VERSION ""

NS_ :

BS_:

BU_: FUSION TBOX

BO_ 1296 NMm_XXX: 8 TBOX

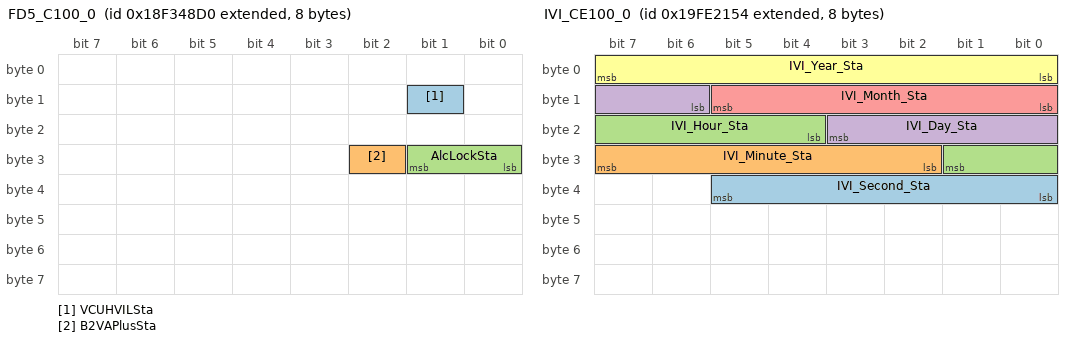
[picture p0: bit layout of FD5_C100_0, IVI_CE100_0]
BO_ 2566080720 FD5_C100_0: 8 FUSION
 SG_ VCUHVILSta : 9|1@1+ (1,0) [0|1] "" Vector__XXX
 SG_ B2VAPlusSta : 26|1@1+ (1,0) [0|1] "" Vector__XXX
 SG_ AlcLockSta : 24|2@1+ (1,0) [0|3] "" Vector__XXX

BO_ 2583568724 IVI_CE100_0: 8 FUSION
 SG_ IVI_Second_Sta : 32|6@1+ (1,0) [0|60] "second"  TBOX
 SG_ IVI_Minute_Sta : 26|6@1+ (1,0) [0|60] "minute"  TBOX
 SG_ IVI_Hour_Sta : 20|6@1+ (1,0) [0|23] "hour"  TBOX
 SG_ IVI_Day_Sta : 14|6@1+ (1,0) [0|31] "day"  TBOX
 SG_ IVI_Month_Sta : 8|6@1+ (1,0) [0|13] "month"  TBOX
 SG_ IVI_Year_Sta : 0|8@1+ (1,2000) [2000|2127] "year"  TBOX

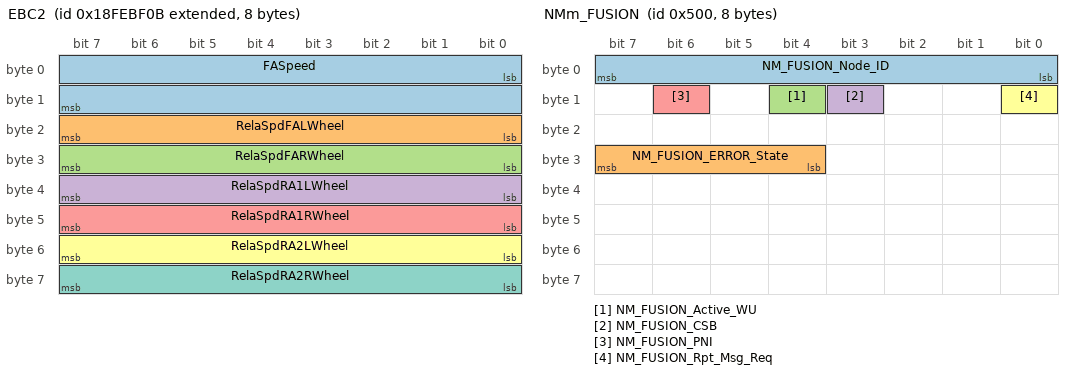
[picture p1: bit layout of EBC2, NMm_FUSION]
BO_ 2566831883 EBC2: 8 FUSION
 SG_ FASpeed : 0|16@1+ (0.00390625,0) [0|255.99609375] "km/h"  TBOX
 SG_ RelaSpdFALWheel : 16|8@1+ (0.0625,-7.8125) [-7.8125|7.8125] "km/h" Vector__XXX
 SG_ RelaSpdFARWheel : 24|8@1+ (0.0625,-7.8125) [-7.8125|7.8125] "km/h" Vector__XXX
 SG_ RelaSpdRA1LWheel : 32|8@1+ (0.0625,-7.8125) [-7.8125|7.8125] "km/h" Vector__XXX
 SG_ RelaSpdRA1RWheel : 40|8@1+ (0.0625,-7.8125) [-7.8125|7.8125] "km/h" Vector__XXX
 SG_ RelaSpdRA2LWheel : 48|8@1+ (0.0625,-7.8125) [-7.8125|7.8125] "km/h" Vector__XXX
 SG_ RelaSpdRA2RWheel : 56|8@1+ (0.0625,-7.8125) [-7.8125|7.8125] "km/h" Vector__XXX

BO_ 525 FD5_C200_0: 32 FUSION
 SG_ SysPowerMode : 0|4@1+ (1,0) [0|15] ""  TBOX

BO_ 2000 DiagFuncReqFT: 8 FUSION
 SG_ DiagFuncReqFT : 7|64@0+ (1,0) [0|1.84467440737096E+019] ""  TBOX

BO_ 1744 DiagPhysReqToTBOX: 64 FUSION
 SG_ DiagPhysReqToTBOX : 71|64@0+ (1,0) [0|1.84467440737096E+019] ""  TBOX

BO_ 1616 DiagRespFromTBOX: 64 TBOX
 SG_ DiagResFromTBOX : 71|64@0+ (1,0) [0|1.84467440737096E+019] ""  FUSION

BO_ 1280 NMm_FUSION: 8 FUSION
 SG_ NM_FUSION_Node_ID : 7|8@0+ (1,0) [0|255] "" Vector__XXX
 SG_ NM_FUSION_ERROR_State : 31|4@0+ (1,0) [0|15] "" Vector__XXX
 SG_ NM_FUSION_Active_WU : 12|1@0+ (1,0) [0|1] "" Vector__XXX
 SG_ NM_FUSION_CSB : 11|1@0+ (1,0) [0|1] "" Vector__XXX
 SG_ NM_FUSION_PNI : 14|1@0+ (1,0) [0|1] "" Vector__XXX
 SG_ NM_FUSION_Rpt_Msg_Req : 8|1@0+ (1,0) [0|1] "" Vector__XXX

CM_ BO_ 2566080720 "FPT1_104.4_Draft，VCU5";
CM_ SG_ 2566080720 VCUHVILSta "偵測接入VCU實體HVIL迴路之狀態，VND紀錄用";
CM_ SG_ 2566080720 B2VAPlusSta "Status of A+ from BCU to VCU";
CM_ SG_ 2566080720 AlcLockSta "酒精鎖狀態";
CM_ SG_ 2583568724 IVI_Second_Sta "IVI_GPS Satellite Time_Second";
CM_ SG_ 2583568724 IVI_Minute_Sta "IVI_GPS Satellite Time_Minute";
CM_ SG_ 2583568724 IVI_Hour_Sta "IVI_GPS Satellite Time_Hour";
CM_ SG_ 2583568724 IVI_Day_Sta "IVI_GPS Satellite Time_Day";
CM_ SG_ 2583568724 IVI_Month_Sta "IVI_GPS Satellite Time_Month";
CM_ SG_ 2583568724 IVI_Year_Sta "IVI_GPS Satellite Time_Year";
CM_ SG_ 2566831883 FASpeed "Front Axle Vehicle Speed(64256~65535=Error)";
CM_ SG_ 2566831883 RelaSpdFALWheel "The speed of the front axle, left wheel relative to the front axle speed, SPN 904.";
CM_ SG_ 2566831883 RelaSpdFARWheel "The speed of the front axle, right wheel relative to the front axle speed, SPN 904.";
CM_ SG_ 2566831883 RelaSpdRA1LWheel "The speed of the rear axle #1, left wheel relative to the front axle speed, SPN 904.";
CM_ SG_ 2566831883 RelaSpdRA1RWheel "The speed of the rear axle #1, right wheel relative to the front axle speed, SPN 904.";
CM_ SG_ 2566831883 RelaSpdRA2LWheel "The speed of the rear axle #2, left wheel relative to the front axle speed, SPN 904.";
CM_ SG_ 2566831883 RelaSpdRA2RWheel "The speed of the rear axle #2, right wheel relative to the front axle speed, SPN 904.";
CM_ BO_ 525 "FPT1_104.4_Draft，VCU3";
CM_ SG_ 525 SysPowerMode "HV system current power mode";
CM_ SG_ 2000 DiagFuncReqFT "Diagnostic Functional Request from Tester";
CM_ SG_ 1744 DiagPhysReqToTBOX "TBOX Diagnostic Request";
CM_ SG_ 1616 DiagResFromTBOX "TBOX Diagnostic Response";
CM_ SG_ 1280 NM_FUSION_Node_ID "Source Node Identifier";
CM_ SG_ 1280 NM_FUSION_ERROR_State "Defined Error states of the CAN Controller";
CM_ SG_ 1280 NM_FUSION_Active_WU "Active Wakeup Bit";
CM_ SG_ 1280 NM_FUSION_CSB "NM Coordinator Sleep Bit";
CM_ SG_ 1280 NM_FUSION_PNI "Partial Network Information Bit (PNI)";
CM_ SG_ 1280 NM_FUSION_Rpt_Msg_Req "Repeat Message Request";
BA_DEF_ SG_  "GenSigInvalidValue" HEX 0 0;
BA_DEF_ SG_  "GenSigStartValue" HEX 0 0;
BA_DEF_ SG_  "GenSigRoutingTimeoutValue_String" STRING ;
BA_DEF_ SG_  "GenSigRoutingTimeoutValue" HEX 0 0;
BA_DEF_ SG_  "GenSigSendType" ENUM  "Cycle","OnWrite","OnWriteWithRepetition","OnChange","OnChangeWithRepetition","IfActive","IfActiveWithRepetition","NoSigSendType","vector_leerstring";
BA_DEF_ SG_  "SigType" ENUM  "Default","Range","RangeSigned","ASCII","Discrete","Control","ReferencePGN","DTC","StringDelimiter","StringLength","StringLengthControl","MessageCounter","MessageChecksum";
BA_DEF_ SG_  "GenSigILSupport" ENUM  "No","Yes";
BA_DEF_ BU_  "NodeLayerModules" STRING ;
BA_DEF_ BU_  "NmCAN" INT 1 2;
BA_DEF_ BU_  "ILUsed" ENUM  "No","Yes";
BA_DEF_ BU_  "CANFD_CANFD_Gateway" ENUM  "Yes","No";
BA_DEF_ BU_  "CAN_CANFD_Gateway" ENUM  "Yes","No";
BA_DEF_ BU_  "CAN_CAN_Gateway" ENUM  "Yes","No";
BA_DEF_  "NmType" STRING ;
BA_DEF_  "VersionYear" INT 2010 2999;
BA_DEF_  "ProtocolType" STRING ;
BA_DEF_  "NmMessageCount" INT 0 255;
BA_DEF_  "NmBaseAddress" HEX 1280 1407;
BA_DEF_  "DBName" STRING ;
BA_DEF_  "BusType" STRING ;
BA_DEF_  "Baudrate" INT 0 1000000;
BA_DEF_  "Datarate" INT 0 2000000;
BA_DEF_ BO_  "GenMsgSendType" ENUM  "Cycle","NoMsgSendType","IfActive","Event","CA","CE";
BA_DEF_ BO_  "GenMsgNrOfRepetition" INT 0 0;
BA_DEF_ BO_  "GenMsgILSupport" ENUM  "No","Yes";
BA_DEF_ BO_  "GenMsgCycleTime" INT 0 0;
BA_DEF_ BO_  "VFrameFormat" ENUM  "StandardCAN","ExtendedCAN","reserved","reserved","reserved","reserved","reserved","reserved","reserved","reserved","reserved","reserved","reserved","reserved","StandardCAN_FD","ExtendedCAN_FD";
BA_DEF_ BO_  "DoIPLogicalAddress" STRING ;
BA_DEF_ BO_  "GenMsgRequestable" INT 0 0;
BA_DEF_ BO_  "CANFD_BRS" ENUM  "0","1";
BA_DEF_DEF_  "GenSigInvalidValue" 0;
BA_DEF_DEF_  "GenSigStartValue" 0;
BA_DEF_DEF_  "GenSigRoutingTimeoutValue_String" "";
BA_DEF_DEF_  "GenSigRoutingTimeoutValue" 0;
BA_DEF_DEF_  "GenSigSendType" "Cycle";
BA_DEF_DEF_  "SigType" "Default";
BA_DEF_DEF_  "GenSigILSupport" "Yes";
BA_DEF_DEF_  "NodeLayerModules" "CANoeILNLVector.dll";
BA_DEF_DEF_  "NmCAN" 2;
BA_DEF_DEF_  "ILUsed" "Yes";
BA_DEF_DEF_  "CANFD_CANFD_Gateway" "No";
BA_DEF_DEF_  "CAN_CANFD_Gateway" "No";
BA_DEF_DEF_  "CAN_CAN_Gateway" "No";
BA_DEF_DEF_  "NmType" "AUTOSAR";
BA_DEF_DEF_  "VersionYear" 2024;
BA_DEF_DEF_  "ProtocolType" "CAN";
BA_DEF_DEF_  "NmMessageCount" 128;
BA_DEF_DEF_  "NmBaseAddress" 1280;
BA_DEF_DEF_  "DBName" "";
BA_DEF_DEF_  "BusType" "CAN";
BA_DEF_DEF_  "Baudrate" 500000;
BA_DEF_DEF_  "Datarate" 2000000;
BA_DEF_DEF_  "GenMsgSendType" "Cycle";
BA_DEF_DEF_  "GenMsgNrOfRepetition" 0;
BA_DEF_DEF_  "GenMsgILSupport" "Yes";
BA_DEF_DEF_  "GenMsgCycleTime" 100;
BA_DEF_DEF_  "VFrameFormat" "StandardCAN";
BA_DEF_DEF_  "DoIPLogicalAddress" "";
BA_DEF_DEF_  "GenMsgRequestable" 1;
BA_DEF_DEF_  "CANFD_BRS" "1";
BA_ "ProtocolType" "CAN FD";
BA_ "BusType" "CAN FD";
BA_ "DBName" "CAN5";
BA_ "CAN_CANFD_Gateway" BU_ FUSION 0;
BA_ "CANFD_CANFD_Gateway" BU_ FUSION 0;
BA_ "CAN_CAN_Gateway" BU_ FUSION 0;
BA_ "GenMsgCycleTime" BO_ 1296 0;
BA_ "GenMsgSendType" BO_ 1296 3;
BA_ "VFrameFormat" BO_ 2566080720 1;
BA_ "GenMsgSendType" BO_ 2583568724 5;
BA_ "VFrameFormat" BO_ 2583568724 1;
BA_ "GenMsgNrOfRepetition" BO_ 2583568724 1;
BA_ "VFrameFormat" BO_ 2566831883 1;
BA_ "GenMsgCycleTime" BO_ 525 200;
BA_ "VFrameFormat" BO_ 525 14;
BA_ "DoIPLogicalAddress" BO_ 2000 "0xEFFF";
BA_ "GenMsgSendType" BO_ 2000 3;
BA_ "GenMsgCycleTime" BO_ 2000 0;
BA_ "DoIPLogicalAddress" BO_ 1744 "0x06D0";
BA_ "GenMsgSendType" BO_ 1744 3;
BA_ "GenMsgCycleTime" BO_ 1744 0;
BA_ "VFrameFormat" BO_ 1744 14;
BA_ "DoIPLogicalAddress" BO_ 1616 "0x06D0";
BA_ "GenMsgSendType" BO_ 1616 3;
BA_ "GenMsgCycleTime" BO_ 1616 0;
BA_ "VFrameFormat" BO_ 1616 14;
BA_ "GenMsgSendType" BO_ 1280 3;
BA_ "GenMsgCycleTime" BO_ 1280 0;
BA_ "GenSigRoutingTimeoutValue" SG_ 2566080720 VCUHVILSta 1;
BA_ "GenSigRoutingTimeoutValue_String" SG_ 2566080720 VCUHVILSta "0x1";
BA_ "GenSigRoutingTimeoutValue" SG_ 2566080720 AlcLockSta 2;
BA_ "GenSigRoutingTimeoutValue_String" SG_ 2566080720 AlcLockSta "0x2";
BA_ "GenSigSendType" SG_ 2583568724 IVI_Second_Sta 3;
BA_ "GenSigInvalidValue" SG_ 2583568724 IVI_Second_Sta 60;
BA_ "GenSigSendType" SG_ 2583568724 IVI_Minute_Sta 3;
BA_ "GenSigInvalidValue" SG_ 2583568724 IVI_Minute_Sta 60;
BA_ "GenSigSendType" SG_ 2583568724 IVI_Hour_Sta 3;
BA_ "GenSigSendType" SG_ 2583568724 IVI_Day_Sta 3;
BA_ "GenSigSendType" SG_ 2583568724 IVI_Month_Sta 3;
BA_ "GenSigSendType" SG_ 2583568724 IVI_Year_Sta 3;
BA_ "GenSigRoutingTimeoutValue" SG_ 2566831883 FASpeed 64256;
BA_ "GenSigRoutingTimeoutValue_String" SG_ 2566831883 FASpeed "0xFB00";
BA_ "GenSigInvalidValue" SG_ 525 SysPowerMode 15;
BA_ "GenSigSendType" SG_ 2000 DiagFuncReqFT 3;
BA_ "GenSigSendType" SG_ 1744 DiagPhysReqToTBOX 3;
BA_ "GenSigSendType" SG_ 1616 DiagResFromTBOX 3;
BA_ "GenSigSendType" SG_ 1280 NM_FUSION_Node_ID 7;
BA_ "GenSigSendType" SG_ 1280 NM_FUSION_ERROR_State 7;
BA_ "GenSigSendType" SG_ 1280 NM_FUSION_Active_WU 7;
BA_ "GenSigSendType" SG_ 1280 NM_FUSION_CSB 7;
BA_ "GenSigSendType" SG_ 1280 NM_FUSION_PNI 7;
BA_ "GenSigSendType" SG_ 1280 NM_FUSION_Rpt_Msg_Req 7;
VAL_ 2566080720 VCUHVILSta 1 "HVIL fail" 0 "HVIL OK" ;
VAL_ 2566080720 B2VAPlusSta 1 "request A+" 0 "not request A+" ;
VAL_ 2566080720 AlcLockSta 2 "NG" 1 "Pass" 0 "Default" ;
VAL_ 2583568724 IVI_Second_Sta 60 "Invalid Value" ;
VAL_ 2583568724 IVI_Minute_Sta 60 "Invalid Value" ;
VAL_ 2583568724 IVI_Month_Sta 13 "Invalid Value" ;
VAL_ 2566831883 FASpeed 64256 "Invalid Value" ;
VAL_ 525 SysPowerMode 8 "LV Batt Charge" 7 "Charge" 6 "Afterrun" 5 "sleep" 4 "Power down" 3 "Drive" 2 "Power up" 1 "stand by" 0 "self checking" ;
VAL_ 1280 NM_FUSION_ERROR_State 8 "BUS OFF_L2" 4 "BUS OFF_L1" 2 "ERROR PASSIVE" 1 "ERROR ACTIVE" 0 "Inactive" ;
VAL_ 1280 NM_FUSION_Active_WU 1 "Node has woken up the network (active Wakeup)" 0 "Node has not woken up the network (passive wakeup)" ;
VAL_ 1280 NM_FUSION_CSB 1 "Start of synchronized shutdown is requested by main coordinator" 0 "Start of synchronized shutdown is not requested by main coordinator" ;
VAL_ 1280 NM_FUSION_PNI 1 "NM PDU contains Partial Network request information" 0 "NM PDU contains no Partial Network request information" ;
VAL_ 1280 NM_FUSION_Rpt_Msg_Req 1 "Repeat Message State requested" 0 "Repeat Message State not requested" ;
